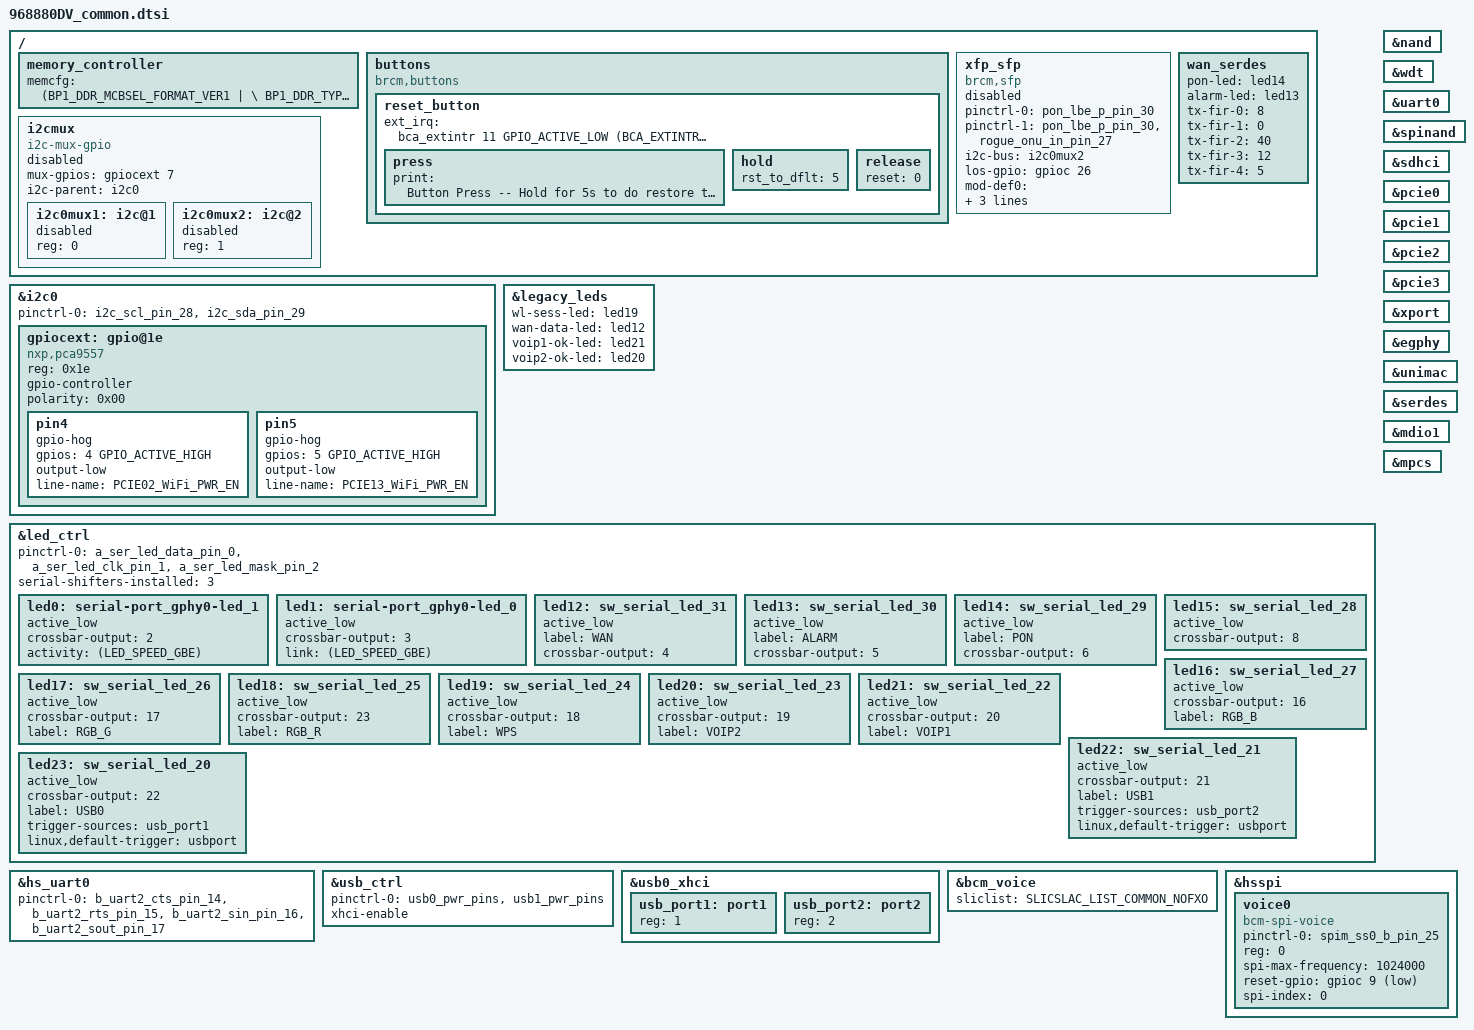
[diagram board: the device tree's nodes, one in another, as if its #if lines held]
#include "68880.dtsi"
#include "../../bcm_voice.dtsi"

/ {
        memory_controller {
                memcfg = <(BP1_DDR_MCBSEL_FORMAT_VER1   | \
                                        BP1_DDR_TYPE_LPDDR4         | \
                                        BP1_DDR_SPEED_2133_36_39_39 | \
                                        BP1_DDR_WIDTH_32BIT         | \
                                        BP1_DDR_TOTAL_SIZE_8Gb      | \
                                        BP1_DDR_SSC_CONFIG_1        | \
					BP1_DDR_CONFIG_DEBUG)>;
        };
};

/ {

        buttons {
                compatible = "brcm,buttons";
                reset_button {
                        ext_irq = <&bca_extintr 11 GPIO_ACTIVE_LOW (BCA_EXTINTR_TYPE_LOW_LEVEL | BCA_EXTINTR_TYPE_SENSE_EDGE)>;
                        press {
                                print = "Button Press -- Hold for 5s to do restore to default";
                        };
                        hold {
                                rst_to_dflt = <5>;
                        };
                        release {
                                reset = <0>;
                        };
                };
        };

        xfp_sfp: xfp_sfp {
                status = "disabled";
                pinctrl-names = "default", "tx-sd";
                pinctrl-0 = <&pon_lbe_p_pin_30>;
                pinctrl-1 = <&pon_lbe_p_pin_30 &rogue_onu_in_pin_27>;
                compatible = "brcm,sfp";
                i2c-bus = <&i2c0mux2>;
                los-gpio = <&gpioc 26 GPIO_ACTIVE_HIGH>;
                mod-def0 = <&bca_extintr 76 GPIO_ACTIVE_LOW (BCA_EXTINTR_TYPE_BOTH_EDGE | BCA_EXTINTR_TYPE_SENSE_EDGE)>;
                tx-power-gpio = <&gpioc 6 GPIO_ACTIVE_HIGH>;
                tx-power-down-gpio = <&gpiocext 6 GPIO_ACTIVE_HIGH>;
        };

        wan_serdes {
                status = "okay";
                pon-led = <&led14>;
                alarm-led = <&led13>;
                tx-fir-0 = "8";
                tx-fir-1 = "0";
                tx-fir-2 = "40";
                tx-fir-3 = "12";
                tx-fir-4 = "5";
        };

        i2cmux {
                status = "disabled";
                compatible = "i2c-mux-gpio";
                #address-cells = <1>;
                #size-cells = <0>;
                mux-gpios = <&gpiocext 7 GPIO_ACTIVE_HIGH>;
                i2c-parent = <&i2c0>;

                i2c0mux1: i2c@1 {
                    status = "disabled";
                    reg = <0>;
                    #address-cells = <1>;
                    #size-cells = <0>;
                };

                i2c0mux2: i2c@2 {
                    status = "disabled";
                    reg = <1>;
                    #address-cells = <1>;
                    #size-cells = <0>;
                };
        };
};

&i2c0 {
        pinctrl-0 = <&i2c_scl_pin_28 &i2c_sda_pin_29>;
        pinctrl-names = "default";
        status = "okay";

    gpiocext: gpio@1e {
           compatible = "nxp,pca9557";
           reg = <0x1e>;
           #gpio-cells = <2>;
           gpio-controller;
           polarity = <0x00>;
           pin4 {
               gpio-hog;
               gpios = <4 GPIO_ACTIVE_HIGH>;
               output-low;
               line-name = "PCIE02_WiFi_PWR_EN";
           };
           pin5 {
               gpio-hog;
               gpios = <5 GPIO_ACTIVE_HIGH>;
               output-low;
               line-name = "PCIE13_WiFi_PWR_EN";
           };
    };
};

&legacy_leds {
    wl-sess-led = <&led19>;
    wan-data-led = <&led12>;
    voip1-ok-led = <&led21>;
    voip2-ok-led = <&led20>;
};

&led_ctrl {
        pinctrl-names = "default";
        pinctrl-0 = <&a_ser_led_data_pin_0 &a_ser_led_clk_pin_1 &a_ser_led_mask_pin_2>;
        serial-shifters-installed = <3>;

    led0: serial-port_gphy0-led_1 {
        active_low;
        crossbar-output = <2>;
        activity = <(LED_SPEED_GBE)>;
        status = "okay";
    };

    led1: serial-port_gphy0-led_0 {
        active_low;
        crossbar-output = <3>;
        link = <(LED_SPEED_GBE)>;
        status = "okay";
    };

    led12: sw_serial_led_31 {
        active_low;
        label = "WAN";
        crossbar-output = <4>;
        status = "okay";
    };

    led13: sw_serial_led_30 {
        active_low;
        label = "ALARM";
        crossbar-output = <5>;
        status = "okay";
    };

    led14: sw_serial_led_29 {
        active_low;
        label = "PON";
        crossbar-output = <6>;
        status = "okay";
    };

    led15: sw_serial_led_28 {
        active_low;
        crossbar-output = <8>;
        status = "okay";
    };

    led16: sw_serial_led_27 {
        active_low;
        crossbar-output = <16>;
        label = "RGB_B";
        status = "okay";
    };

    led17: sw_serial_led_26 {
        active_low;
        crossbar-output = <17>;
        label = "RGB_G";
        status = "okay";
    };

    led18: sw_serial_led_25 {
        active_low;
        crossbar-output = <23>;
        label = "RGB_R";
        status = "okay";
    };

    led19: sw_serial_led_24 {
        active_low;
        crossbar-output = <18>;
        label = "WPS";
        status = "okay";
    };

    led20: sw_serial_led_23 {
        active_low;
        crossbar-output = <19>;
        label = "VOIP2";
        status = "okay";
    };

    led21: sw_serial_led_22 {
        active_low;
        crossbar-output = <20>;
        label = "VOIP1";
        status = "okay";
    };

    led22: sw_serial_led_21 {
        active_low;
        crossbar-output = <21>;
        label = "USB1";
        trigger-sources = <&usb_port2>;
        linux,default-trigger = "usbport";
        status = "okay";
    };

    led23: sw_serial_led_20 {
        active_low;
        crossbar-output = <22>;
        label = "USB0";
        trigger-sources = <&usb_port1>;
        linux,default-trigger = "usbport";
        status = "okay";
    };
};

&nand {
        status = "okay";
};
&wdt {
        status = "okay";
};
&uart0 {
        status = "okay";
};

&hs_uart0 {
        pinctrl-0 = <&b_uart2_cts_pin_14 &b_uart2_rts_pin_15 &b_uart2_sin_pin_16 &b_uart2_sout_pin_17>;
        pinctrl-names = "default";
        status = "okay";
};

&spinand {
        status = "okay";
};

&sdhci {
    status = "okay";
};

&usb_ctrl {
        pinctrl-names = "default";
        pinctrl-0 = <&usb0_pwr_pins &usb1_pwr_pins>;
        xhci-enable;
        status = "okay";
};

&usb0_xhci {
        status = "okay";
        usb_port1: port1 {
            reg = <1>;
            #trigger-source-cells = <0>;
        };

        usb_port2: port2 {
            reg = <2>;
            #trigger-source-cells = <0>;
        };
};

#if defined(CONFIG_BCM_PCIE_HCD) || defined(CONFIG_BCM_PCIE_HCD_MODULE)
&pcie0 {
        status = "okay";
};
&pcie1 {
        status = "okay";
};
&pcie2 {
        status = "okay";
};
&pcie3 {
        status = "okay";
};
#endif

&xport {
    status = "okay";
};

&egphy {
    status = "okay";
};

&unimac {
    status = "okay";
};

&serdes {
    status = "okay";
};

&mdio1 {
    status = "okay";
};

&mpcs {
    status = "okay";
};

&bcm_voice {
        sliclist = SLICSLAC_LIST_COMMON_NOFXO;
};

&hsspi {
        status = "okay";
        voice0 {
                pinctrl-0 = <&spim_ss0_b_pin_25>;
                pinctrl-names = "default";
                compatible = "bcm-spi-voice";
                reg = <0>; /* chip select 0 */
                spi-max-frequency = <1024000>;
                reset-gpio = <&gpioc 9 GPIO_ACTIVE_LOW>;
                spi-index = <0>;/* voice header index */
        };
};
